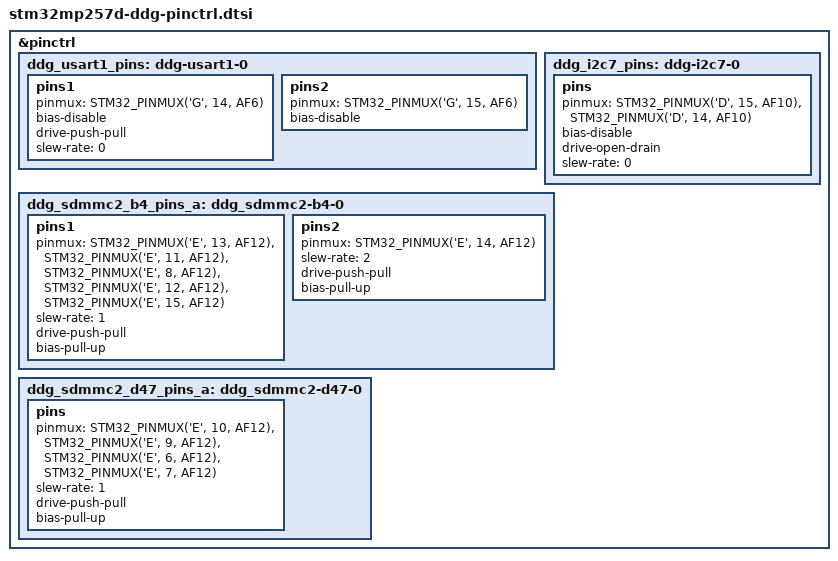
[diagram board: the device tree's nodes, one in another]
#include <dt-bindings/pinctrl/stm32-pinfunc.h>

&pinctrl {
	/omit-if-no-ref/
	ddg_usart1_pins: ddg-usart1-0 {
		pins1 {
			pinmux = <STM32_PINMUX('G', 14, AF6)>; /* USART1_TX */
			bias-disable;
			drive-push-pull;
			slew-rate = <0>;
		};

		pins2 {
			pinmux = <STM32_PINMUX('G', 15, AF6)>; /* USART1_RX */
			bias-disable;
		};
	};

    /omit-if-no-ref/
    ddg_i2c7_pins: ddg-i2c7-0 {
        pins {
            pinmux = <STM32_PINMUX('D', 15, AF10)>,
                     <STM32_PINMUX('D', 14, AF10)>;
            bias-disable;
            drive-open-drain;
            slew-rate = <0>;
        };
    };

    /omit-if-no-ref/
	ddg_sdmmc2_b4_pins_a: ddg_sdmmc2-b4-0 {
		pins1 {
			pinmux = <STM32_PINMUX('E', 13, AF12)>, /* SDMMC2_D0 */
                     <STM32_PINMUX('E', 11, AF12)>,     /* SDMMC2_D1 */
                     <STM32_PINMUX('E', 8, AF12)>,      /* SDMMC2_D2 */
                     <STM32_PINMUX('E', 12, AF12)>,     /* SDMMC2_D3 */
                     <STM32_PINMUX('E', 15, AF12)>;     /* SDMMC2_CMD */
			slew-rate = <1>;
			drive-push-pull;
			bias-pull-up;
		};
		pins2 {
			pinmux = <STM32_PINMUX('E', 14, AF12)>; /* SDMMC2_CK */
			slew-rate = <2>;
			drive-push-pull;
			bias-pull-up;
		};
	};

    /omit-if-no-ref/
	ddg_sdmmc2_d47_pins_a: ddg_sdmmc2-d47-0 {
		pins {
			pinmux = <STM32_PINMUX('E', 10, AF12)>, /* SDMMC2_D4 */
                     <STM32_PINMUX('E', 9, AF12)>,      /* SDMMC2_D5 */
                     <STM32_PINMUX('E', 6, AF12)>,      /* SDMMC2_D6 */
                     <STM32_PINMUX('E', 7, AF12)>;      /* SDMMC2_D7 */
			slew-rate = <1>;
			drive-push-pull;
			bias-pull-up;
		};
	};

};
